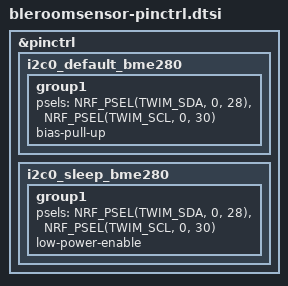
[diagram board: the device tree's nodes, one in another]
&pinctrl {
    i2c0_default_bme280: i2c0_default_bme280 {
        group1 {
            psels =
              <NRF_PSEL(TWIM_SDA, 0, 28)>,
				      <NRF_PSEL(TWIM_SCL, 0, 30)>;
            bias-pull-up;
        };
    };

    i2c0_sleep_bme280: i2c0_sleep_bme280 {
        group1 {
            psels =
            <NRF_PSEL(TWIM_SDA, 0, 28)>,
				    <NRF_PSEL(TWIM_SCL, 0, 30)>;
            low-power-enable;
        };
    };
};
